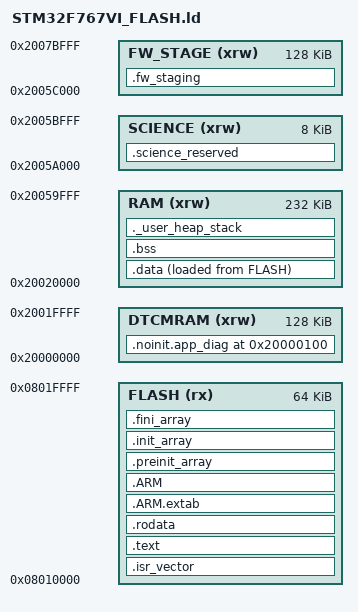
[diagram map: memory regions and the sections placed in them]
/*
*****************************************************************************
**

**  File        : stm32_flash.ld
**
**  Abstract    : Linker script for STM32F767VI Device with
**                2048KByte FLASH, 512KByte RAM
**
**                Set heap size, stack size and stack location according
**                to application requirements.
**
**                Set memory bank area and size if external memory is used.
**
**  Target      : STMicroelectronics STM32
**
**  Environment : Atollic TrueSTUDIO(R)
**
**  Distribution: The file is distributed as is, without any warranty
**                of any kind.
**
**  (c)Copyright Atollic AB.
**  You may use this file as-is or modify it according to the needs of your
**  project. This file may only be built (assembled or compiled and linked)
**  using the Atollic TrueSTUDIO(R) product. The use of this file together
**  with other tools than Atollic TrueSTUDIO(R) is not permitted.
**
*****************************************************************************
*/

/* Entry Point */
ENTRY(Reset_Handler)

/* Highest address of the user mode stack */
_estack = 0x20080000;    /* end of RAM */
/* Generate a link error if heap and stack don't fit into RAM */
_Min_Heap_Size = 0x200;      /* required amount of heap  */
_Min_Stack_Size = 0x400; /* required amount of stack */

/* Specify the memory areas */
MEMORY
{
  DTCMRAM (xrw) : ORIGIN = 0x20000000, LENGTH = 128K
  RAM     (xrw) : ORIGIN = 0x20020000, LENGTH = 232K
  SCIENCE (xrw) : ORIGIN = 0x2005A000, LENGTH = 8K
  FW_STAGE (xrw) : ORIGIN = 0x2005C000, LENGTH = 128K
  FLASH   (rx)  : ORIGIN = 0x08010000, LENGTH = 64K
}

/* Define output sections */
SECTIONS
{
  /* The startup code goes first into FLASH */
  .isr_vector :
  {
    . = ALIGN(4);
    KEEP(*(.isr_vector)) /* Startup code */
    . = ALIGN(4);
  } >FLASH

  /* The program code and other data goes into FLASH */
  .text :
  {
    . = ALIGN(4);
    *(.text)           /* .text sections (code) */
    *(.text*)          /* .text* sections (code) */
    *(.glue_7)         /* glue arm to thumb code */
    *(.glue_7t)        /* glue thumb to arm code */
    *(.eh_frame)

    KEEP (*(.init))
    KEEP (*(.fini))

    . = ALIGN(4);
    _etext = .;        /* define a global symbols at end of code */
  } >FLASH

  /* Constant data goes into FLASH */
  .rodata :
  {
    . = ALIGN(4);
    *(.rodata)         /* .rodata sections (constants, strings, etc.) */
    *(.rodata*)        /* .rodata* sections (constants, strings, etc.) */
    . = ALIGN(4);
  } >FLASH

  .ARM.extab (READONLY) : { *(.ARM.extab* .gnu.linkonce.armextab.*) } >FLASH
  .ARM (READONLY) : {
    __exidx_start = .;
    *(.ARM.exidx*)
    __exidx_end = .;
  } >FLASH

  .preinit_array (READONLY) :
  {
    PROVIDE_HIDDEN (__preinit_array_start = .);
    KEEP (*(.preinit_array*))
    PROVIDE_HIDDEN (__preinit_array_end = .);
  } >FLASH
  .init_array (READONLY) :
  {
    PROVIDE_HIDDEN (__init_array_start = .);
    KEEP (*(SORT(.init_array.*)))
    KEEP (*(.init_array*))
    PROVIDE_HIDDEN (__init_array_end = .);
  } >FLASH
  .fini_array (READONLY) :
  {
    PROVIDE_HIDDEN (__fini_array_start = .);
    KEEP (*(SORT(.fini_array.*)))
    KEEP (*(.fini_array*))
    PROVIDE_HIDDEN (__fini_array_end = .);
  } >FLASH

  /* used by the startup to initialize data */
  _sidata = LOADADDR(.data);

  /* Initialized data sections goes into RAM, load LMA copy after code */
  .data : 
  {
    . = ALIGN(4);
    _sdata = .;        /* create a global symbol at data start */
    *(.data)           /* .data sections */
    *(.data*)          /* .data* sections */

    . = ALIGN(4);
    _edata = .;        /* define a global symbol at data end */
  } >RAM AT> FLASH

  
  /* Uninitialized data section */
  . = ALIGN(4);
  .bss :
  {
    /* This is used by the startup in order to initialize the .bss secion */
    _sbss = .;         /* define a global symbol at bss start */
    __bss_start__ = _sbss;
    *(.bss)
    *(.bss*)
    *(COMMON)

    . = ALIGN(4);
    _ebss = .;         /* define a global symbol at bss end */
    __bss_end__ = _ebss;
  } >RAM

  /* Deliberately empty: this address range is reserved for science data. */
  .science_reserved (NOLOAD) :
  {
    __science_reserved_start__ = ORIGIN(SCIENCE);
    __science_reserved_end__ = ORIGIN(SCIENCE) + LENGTH(SCIENCE);
  } >SCIENCE

  /* Link-check the upload buffer against its dedicated 128 KiB region. */
  .fw_staging (NOLOAD) :
  {
    . = ALIGN(32);
    __fw_staging_start__ = .;
    KEEP(*(.fw_staging))
    . = ALIGN(32);
    __fw_staging_end__ = .;
  } >FW_STAGE

  /* Small system-reset-retained diagnostics in otherwise unused DTCM. */
  .noinit.app_diag 0x20000100 (NOLOAD) :
  {
    . = ALIGN(8);
    KEEP(*(.noinit.app_diag))
    . = ALIGN(8);
  } >DTCMRAM

  /* User_heap_stack section, used to check that there is enough RAM left */
  ._user_heap_stack :
  {
    . = ALIGN(4);
    PROVIDE ( end = . );
    PROVIDE ( _end = . );
    . = . + _Min_Heap_Size;
    . = . + _Min_Stack_Size;
    . = ALIGN(4);
  } >RAM

  

  /* Remove information from the standard libraries */
  /DISCARD/ :
  {
    libc.a ( * )
    libm.a ( * )
    libgcc.a ( * )
  }

  .ARM.attributes 0 : { *(.ARM.attributes) }
}
